VERSION ""

NS_ :

BS_:

BU_:

BO_ 304 HS_CAN3__neoVI_3G___130: 5 Vector__XXX
 SG_ Pedal_Accel_Pos_CAN3___ : 39|8@0+ (0.393162,0) [0|100.2564102564103] "%" Vector__XXX

BO_ 804 HS_CAN3__neoVI_3G___324: 0 Vector__XXX

BO_ 780 HS_CAN3__neoVI_3G___30C: 6 Vector__XXX
 SG_ Veh_ACC_distance_set_CAN__ : 47|2@0+ (1,0) [0|3] "" Vector__XXX
 SG_ Veh_ACC_standard_mode_active_CAN__ : 40|1@0+ (1,0) [0|1.0] "" Vector__XXX

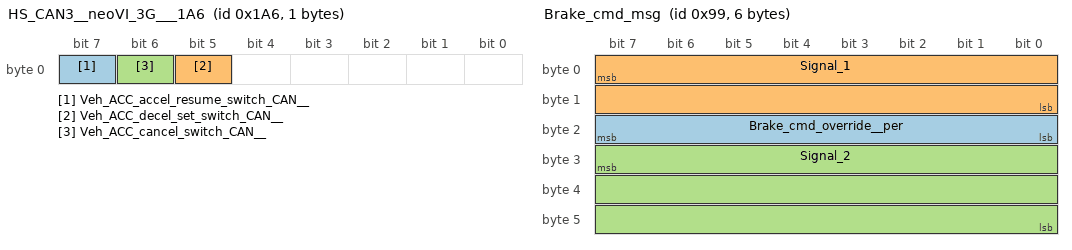
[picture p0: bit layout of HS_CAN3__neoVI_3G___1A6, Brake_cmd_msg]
BO_ 422 HS_CAN3__neoVI_3G___1A6: 1 Vector__XXX
 SG_ Veh_ACC_accel_resume_switch_CAN__ : 7|1@0+ (1,0) [0|0] "" Vector__XXX
 SG_ Veh_ACC_decel_set_switch_CAN__ : 5|1@0+ (1,0) [0|0] "" Vector__XXX
 SG_ Veh_ACC_cancel_switch_CAN__ : 6|1@0+ (1,0) [0|0] "" Vector__XXX

BO_ 153 Brake_cmd_msg: 6 Vector__XXX
 SG_ Brake_cmd_override__per : 23|8@0+ (0.392157,0) [0|100.000035] "%" Vector__XXX
 SG_ Signal_1 : 7|16@0+ (1,0) [0|65535] "" Vector__XXX
 SG_ Signal_2 : 31|24@0+ (1,0) [0|16777215] "" Vector__XXX

BO_ 506 Message_HS_CAN3__neoVI_3G__52: 8 Vector__XXX
 SG_ brake_command_ACC_Moduel_CAN3__per : 55|8@0+ (0.392157,0) [0|100.000035] "%" Vector__XXX
